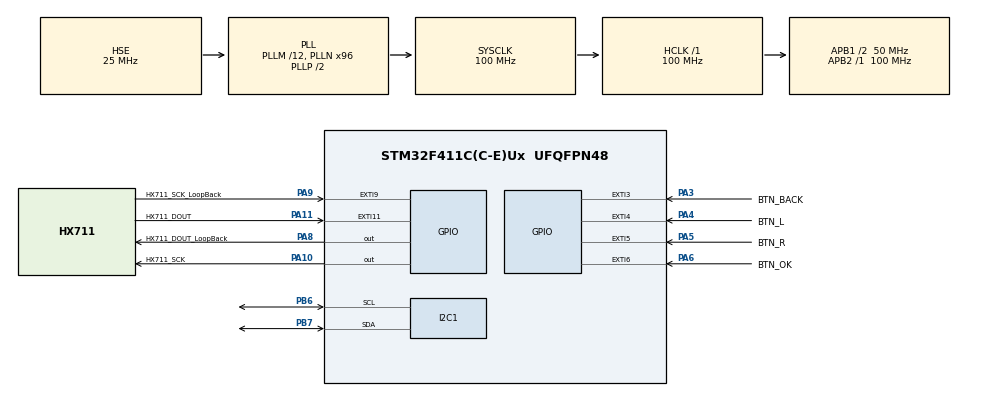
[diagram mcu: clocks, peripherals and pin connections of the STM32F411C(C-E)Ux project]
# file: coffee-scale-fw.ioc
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I2C1.I2C_Mode=I2C_Fast
Mcu.Family=STM32F4
Mcu.Name=STM32F411C(C-E)Ux
Mcu.Package=UFQFPN48
NVIC.EXTI15_10_IRQn=true\:0\:0\:false\:false\:true\:true\:true\:true
NVIC.EXTI3_IRQn=true\:0\:0\:false\:false\:true\:true\:true\:true
NVIC.EXTI4_IRQn=true\:0\:0\:false\:false\:true\:true\:true\:true
NVIC.EXTI9_5_IRQn=true\:0\:0\:false\:false\:true\:true\:true\:true
NVIC.PriorityGroup=NVIC_PRIORITYGROUP_4
NVIC.TIM2_IRQn=true\:0\:0\:false\:false\:true\:true\:true\:true
NVIC.TIM4_IRQn=true\:0\:0\:false\:false\:true\:true\:true\:true
NVIC.TIM5_IRQn=true\:0\:0\:false\:false\:true\:true\:true\:true
PA10.GPIO_Label=HX711_SCK
PA10.GPIO_Speed=GPIO_SPEED_FREQ_VERY_HIGH
PA10.Signal=GPIO_Output
PA11.GPIO_Label=HX711_DOUT
PA11.GPIO_ModeDefaultEXTI=GPIO_MODE_IT_FALLING
PA11.GPIO_PuPd=GPIO_PULLUP
PA11.Signal=GPXTI11
PA13.Mode=Serial_Wire
PA13.Signal=SYS_JTMS-SWDIO
PA14.Mode=Serial_Wire
PA14.Signal=SYS_JTCK-SWCLK
PA3.GPIO_Label=BTN_BACK
PA3.GPIO_ModeDefaultEXTI=GPIO_MODE_IT_RISING_FALLING
PA3.GPIO_PuPd=GPIO_PULLDOWN
PA3.Signal=GPXTI3
PA4.GPIO_Label=BTN_L
PA4.GPIO_ModeDefaultEXTI=GPIO_MODE_IT_RISING_FALLING
PA4.GPIO_PuPd=GPIO_PULLDOWN
PA4.Signal=GPXTI4
PA5.GPIO_Label=BTN_R
PA5.GPIO_ModeDefaultEXTI=GPIO_MODE_IT_RISING_FALLING
PA5.GPIO_PuPd=GPIO_PULLDOWN
PA5.Signal=GPXTI5
PA6.GPIO_Label=BTN_OK
PA6.GPIO_ModeDefaultEXTI=GPIO_MODE_IT_RISING_FALLING
PA6.GPIO_PuPd=GPIO_PULLDOWN
PA6.Signal=GPXTI6
PA8.GPIO_Label=HX711_DOUT_LoopBack
PA8.GPIO_Speed=GPIO_SPEED_FREQ_VERY_HIGH
PA8.PinState=GPIO_PIN_RESET
PA8.Signal=GPIO_Output
PA9.GPIO_Label=HX711_SCK_LoopBack
PA9.GPIO_PuPd=GPIO_PULLDOWN
PA9.Signal=GPXTI9
PB6.Mode=I2C
PB6.Signal=I2C1_SCL
PB7.Mode=I2C
PB7.Signal=I2C1_SDA
PH0\ -\ OSC_IN.Mode=HSE-External-Oscillator
PH0\ -\ OSC_IN.Signal=RCC_OSC_IN
PH1\ -\ OSC_OUT.Mode=HSE-External-Oscillator
PH1\ -\ OSC_OUT.Signal=RCC_OSC_OUT
ProjectManager.HeapSize=0x200
ProjectManager.StackSize=0x400
ProjectManager.TargetToolchain=STM32CubeIDE
RCC.48MHZClocksFreq_Value=50000000
RCC.AHBFreq_Value=100000000
RCC.APB1CLKDivider=RCC_HCLK_DIV2
RCC.APB1Freq_Value=50000000
RCC.APB1TimFreq_Value=100000000
RCC.APB2Freq_Value=100000000
RCC.APB2TimFreq_Value=100000000
RCC.CortexFreq_Value=100000000
RCC.HCLKFreq_Value=100000000
RCC.HSE_VALUE=25000000
RCC.HSI_VALUE=16000000
RCC.LSE_VALUE=32768
RCC.PLLM=12
RCC.PLLN=96
RCC.PLLSourceVirtual=RCC_PLLSOURCE_HSE
RCC.SYSCLKFreq_VALUE=100000000
RCC.SYSCLKSource=RCC_SYSCLKSOURCE_PLLCLK
RCC.VCOOutputFreq_Value=200000000
TIM2.Channel-Output\ Compare1\ No\ Output=TIM_CHANNEL_1
TIM2.Channel-Output\ Compare2\ No\ Output=TIM_CHANNEL_2
TIM2.Channel-Output\ Compare3\ No\ Output=TIM_CHANNEL_3
TIM2.Channel-Output\ Compare4\ No\ Output=TIM_CHANNEL_4
TIM2.OC1Preload=DISABLE
TIM2.Period=49999
TIM2.Prescaler=399
TIM4.Period=49999
TIM4.Prescaler=399
TIM5.Period=99999
TIM5.Prescaler=999
VP_TIM2_VS_ClockSourceINT.Mode=Internal
VP_TIM2_VS_no_output1.Mode=Output Compare1 No Output
VP_TIM2_VS_no_output2.Mode=Output Compare2 No Output
VP_TIM2_VS_no_output3.Mode=Output Compare3 No Output
VP_TIM2_VS_no_output4.Mode=Output Compare4 No Output
VP_TIM4_VS_ClockSourceINT.Mode=Internal
VP_TIM5_VS_ClockSourceINT.Mode=Internal
board=custom

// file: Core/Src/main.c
/* USER CODE BEGIN Header */
/**
  ******************************************************************************
  * @file           : main.c
  * @brief          : Main program body
  ******************************************************************************
  * @attention
  *
  * Copyright (c) 2026 STMicroelectronics.
  * All rights reserved.
  *
  * This software is licensed under terms that can be found in the LICENSE file
  * in the root directory of this software component.
  * If no LICENSE file comes with this software, it is provided AS-IS.
  *
  ******************************************************************************
  */
/* USER CODE END Header */
#include "main.h"

/* USER CODE BEGIN Includes */
#include "scale_sys.h"
/* USER CODE END Includes */

I2C_HandleTypeDef hi2c1;

TIM_HandleTypeDef htim2;
TIM_HandleTypeDef htim4;
TIM_HandleTypeDef htim5;

void SystemClock_Config(void);
static void MX_GPIO_Init(void);
static void MX_I2C1_Init(void);
static void MX_TIM2_Init(void);
static void MX_TIM5_Init(void);
static void MX_TIM4_Init(void);

/* USER CODE BEGIN 0 */
void buttonCbTest(void) { return; }
/* USER CODE END 0 */

int main(void)
{

  /* MCU Configuration--------------------------------------------------------*/

  /* Reset of all peripherals, Initializes the Flash interface and the Systick. */
  HAL_Init();

  /* Configure the system clock */
  SystemClock_Config();

  /* Initialize all configured peripherals */
  MX_GPIO_Init();
  MX_I2C1_Init();
  MX_TIM2_Init();
  MX_TIM5_Init();
  MX_TIM4_Init();
  /* USER CODE BEGIN 2 */
  ScaleSysInit();
  /* USER CODE END 2 */

  /* Infinite loop */
  while (1)
  {

    /* USER CODE BEGIN 3 */
	  ScaleSysLoop();
  }
  /* USER CODE END 3 */
}

void SystemClock_Config(void)
{
  RCC_OscInitTypeDef RCC_OscInitStruct = {0};
  RCC_ClkInitTypeDef RCC_ClkInitStruct = {0};

  /** Configure the main internal regulator output voltage
  */
  __HAL_RCC_PWR_CLK_ENABLE();
  __HAL_PWR_VOLTAGESCALING_CONFIG(PWR_REGULATOR_VOLTAGE_SCALE1);

  /** Initializes the RCC Oscillators according to the specified parameters
  * in the RCC_OscInitTypeDef structure.
  */
  RCC_OscInitStruct.OscillatorType = RCC_OSCILLATORTYPE_HSE;
  RCC_OscInitStruct.HSEState = RCC_HSE_ON;
  RCC_OscInitStruct.PLL.PLLState = RCC_PLL_ON;
  RCC_OscInitStruct.PLL.PLLSource = RCC_PLLSOURCE_HSE;
  RCC_OscInitStruct.PLL.PLLM = 12;
  RCC_OscInitStruct.PLL.PLLN = 96;
  RCC_OscInitStruct.PLL.PLLP = RCC_PLLP_DIV2;
  RCC_OscInitStruct.PLL.PLLQ = 4;
  if (HAL_RCC_OscConfig(&RCC_OscInitStruct) != HAL_OK)
  {
    Error_Handler();
  }

  /** Initializes the CPU, AHB and APB buses clocks
  */
  RCC_ClkInitStruct.ClockType = RCC_CLOCKTYPE_HCLK|RCC_CLOCKTYPE_SYSCLK
                              |RCC_CLOCKTYPE_PCLK1|RCC_CLOCKTYPE_PCLK2;
  RCC_ClkInitStruct.SYSCLKSource = RCC_SYSCLKSOURCE_PLLCLK;
  RCC_ClkInitStruct.AHBCLKDivider = RCC_SYSCLK_DIV1;
  RCC_ClkInitStruct.APB1CLKDivider = RCC_HCLK_DIV2;
  RCC_ClkInitStruct.APB2CLKDivider = RCC_HCLK_DIV1;

  if (HAL_RCC_ClockConfig(&RCC_ClkInitStruct, FLASH_LATENCY_3) != HAL_OK)
  {
    Error_Handler();
  }
}

static void MX_I2C1_Init(void)
{

  hi2c1.Instance = I2C1;
  hi2c1.Init.ClockSpeed = 400000;
  hi2c1.Init.DutyCycle = I2C_DUTYCYCLE_2;
  hi2c1.Init.OwnAddress1 = 0;
  hi2c1.Init.AddressingMode = I2C_ADDRESSINGMODE_7BIT;
  hi2c1.Init.DualAddressMode = I2C_DUALADDRESS_DISABLE;
  hi2c1.Init.OwnAddress2 = 0;
  hi2c1.Init.GeneralCallMode = I2C_GENERALCALL_DISABLE;
  hi2c1.Init.NoStretchMode = I2C_NOSTRETCH_DISABLE;
  if (HAL_I2C_Init(&hi2c1) != HAL_OK)
  {
    Error_Handler();
  }

}

static void MX_TIM2_Init(void)
{

  TIM_ClockConfigTypeDef sClockSourceConfig = {0};
  TIM_MasterConfigTypeDef sMasterConfig = {0};
  TIM_OC_InitTypeDef sConfigOC = {0};

  htim2.Instance = TIM2;
  htim2.Init.Prescaler = 399;
  htim2.Init.CounterMode = TIM_COUNTERMODE_UP;
  htim2.Init.Period = 49999;
  htim2.Init.ClockDivision = TIM_CLOCKDIVISION_DIV1;
  htim2.Init.AutoReloadPreload = TIM_AUTORELOAD_PRELOAD_DISABLE;
  if (HAL_TIM_Base_Init(&htim2) != HAL_OK)
  {
    Error_Handler();
  }
  sClockSourceConfig.ClockSource = TIM_CLOCKSOURCE_INTERNAL;
  if (HAL_TIM_ConfigClockSource(&htim2, &sClockSourceConfig) != HAL_OK)
  {
    Error_Handler();
  }
  if (HAL_TIM_OC_Init(&htim2) != HAL_OK)
  {
    Error_Handler();
  }
  sMasterConfig.MasterOutputTrigger = TIM_TRGO_RESET;
  sMasterConfig.MasterSlaveMode = TIM_MASTERSLAVEMODE_DISABLE;
  if (HAL_TIMEx_MasterConfigSynchronization(&htim2, &sMasterConfig) != HAL_OK)
  {
    Error_Handler();
  }
  sConfigOC.OCMode = TIM_OCMODE_TIMING;
  sConfigOC.Pulse = 0;
  sConfigOC.OCPolarity = TIM_OCPOLARITY_HIGH;
  sConfigOC.OCFastMode = TIM_OCFAST_DISABLE;
  if (HAL_TIM_OC_ConfigChannel(&htim2, &sConfigOC, TIM_CHANNEL_1) != HAL_OK)
  {
    Error_Handler();
  }
  if (HAL_TIM_OC_ConfigChannel(&htim2, &sConfigOC, TIM_CHANNEL_2) != HAL_OK)
  {
    Error_Handler();
  }
  if (HAL_TIM_OC_ConfigChannel(&htim2, &sConfigOC, TIM_CHANNEL_3) != HAL_OK)
  {
    Error_Handler();
  }
  if (HAL_TIM_OC_ConfigChannel(&htim2, &sConfigOC, TIM_CHANNEL_4) != HAL_OK)
  {
    Error_Handler();
  }

}

static void MX_TIM4_Init(void)
{

  TIM_ClockConfigTypeDef sClockSourceConfig = {0};
  TIM_MasterConfigTypeDef sMasterConfig = {0};

  htim4.Instance = TIM4;
  htim4.Init.Prescaler = 399;
  htim4.Init.CounterMode = TIM_COUNTERMODE_UP;
  htim4.Init.Period = 49999;
  htim4.Init.ClockDivision = TIM_CLOCKDIVISION_DIV1;
  htim4.Init.AutoReloadPreload = TIM_AUTORELOAD_PRELOAD_DISABLE;
  if (HAL_TIM_Base_Init(&htim4) != HAL_OK)
  {
    Error_Handler();
  }
  sClockSourceConfig.ClockSource = TIM_CLOCKSOURCE_INTERNAL;
  if (HAL_TIM_ConfigClockSource(&htim4, &sClockSourceConfig) != HAL_OK)
  {
    Error_Handler();
  }
  sMasterConfig.MasterOutputTrigger = TIM_TRGO_RESET;
  sMasterConfig.MasterSlaveMode = TIM_MASTERSLAVEMODE_DISABLE;
  if (HAL_TIMEx_MasterConfigSynchronization(&htim4, &sMasterConfig) != HAL_OK)
  {
    Error_Handler();
  }

}

static void MX_TIM5_Init(void)
{

  TIM_ClockConfigTypeDef sClockSourceConfig = {0};
  TIM_MasterConfigTypeDef sMasterConfig = {0};

  htim5.Instance = TIM5;
  htim5.Init.Prescaler = 999;
  htim5.Init.CounterMode = TIM_COUNTERMODE_UP;
  htim5.Init.Period = 99999;
  htim5.Init.ClockDivision = TIM_CLOCKDIVISION_DIV1;
  htim5.Init.AutoReloadPreload = TIM_AUTORELOAD_PRELOAD_DISABLE;
  if (HAL_TIM_Base_Init(&htim5) != HAL_OK)
  {
    Error_Handler();
  }
  sClockSourceConfig.ClockSource = TIM_CLOCKSOURCE_INTERNAL;
  if (HAL_TIM_ConfigClockSource(&htim5, &sClockSourceConfig) != HAL_OK)
  {
    Error_Handler();
  }
  sMasterConfig.MasterOutputTrigger = TIM_TRGO_RESET;
  sMasterConfig.MasterSlaveMode = TIM_MASTERSLAVEMODE_DISABLE;
  if (HAL_TIMEx_MasterConfigSynchronization(&htim5, &sMasterConfig) != HAL_OK)
  {
    Error_Handler();
  }

}

static void MX_GPIO_Init(void)
{
  GPIO_InitTypeDef GPIO_InitStruct = {0};

  /* GPIO Ports Clock Enable */
  __HAL_RCC_GPIOH_CLK_ENABLE();
  __HAL_RCC_GPIOA_CLK_ENABLE();
  __HAL_RCC_GPIOB_CLK_ENABLE();

  /*Configure GPIO pin Output Level */
  HAL_GPIO_WritePin(GPIOA, HX711_DOUT_LoopBack_Pin|HX711_SCK_Pin, GPIO_PIN_RESET);

  /*Configure GPIO pins : BTN_BACK_Pin BTN_L_Pin BTN_R_Pin BTN_OK_Pin */
  GPIO_InitStruct.Pin = BTN_BACK_Pin|BTN_L_Pin|BTN_R_Pin|BTN_OK_Pin;
  GPIO_InitStruct.Mode = GPIO_MODE_IT_RISING_FALLING;
  GPIO_InitStruct.Pull = GPIO_PULLDOWN;
  HAL_GPIO_Init(GPIOA, &GPIO_InitStruct);

  /*Configure GPIO pins : HX711_DOUT_LoopBack_Pin HX711_SCK_Pin */
  GPIO_InitStruct.Pin = HX711_DOUT_LoopBack_Pin|HX711_SCK_Pin;
  GPIO_InitStruct.Mode = GPIO_MODE_OUTPUT_PP;
  GPIO_InitStruct.Pull = GPIO_NOPULL;
  GPIO_InitStruct.Speed = GPIO_SPEED_FREQ_VERY_HIGH;
  HAL_GPIO_Init(GPIOA, &GPIO_InitStruct);

  /*Configure GPIO pin : HX711_SCK_LoopBack_Pin */
  GPIO_InitStruct.Pin = HX711_SCK_LoopBack_Pin;
  GPIO_InitStruct.Mode = GPIO_MODE_IT_RISING;
  GPIO_InitStruct.Pull = GPIO_PULLDOWN;
  HAL_GPIO_Init(HX711_SCK_LoopBack_GPIO_Port, &GPIO_InitStruct);

  /*Configure GPIO pin : HX711_DOUT_Pin */
  GPIO_InitStruct.Pin = HX711_DOUT_Pin;
  GPIO_InitStruct.Mode = GPIO_MODE_IT_FALLING;
  GPIO_InitStruct.Pull = GPIO_PULLUP;
  HAL_GPIO_Init(HX711_DOUT_GPIO_Port, &GPIO_InitStruct);

  /* EXTI interrupt init*/
  HAL_NVIC_SetPriority(EXTI3_IRQn, 0, 0);
  HAL_NVIC_EnableIRQ(EXTI3_IRQn);

  HAL_NVIC_SetPriority(EXTI4_IRQn, 0, 0);
  HAL_NVIC_EnableIRQ(EXTI4_IRQn);

  HAL_NVIC_SetPriority(EXTI9_5_IRQn, 0, 0);
  HAL_NVIC_EnableIRQ(EXTI9_5_IRQn);

  HAL_NVIC_SetPriority(EXTI15_10_IRQn, 0, 0);
  HAL_NVIC_EnableIRQ(EXTI15_10_IRQn);

}

void Error_Handler(void)
{
  __disable_irq();
  while (1)
  {
  }
}
